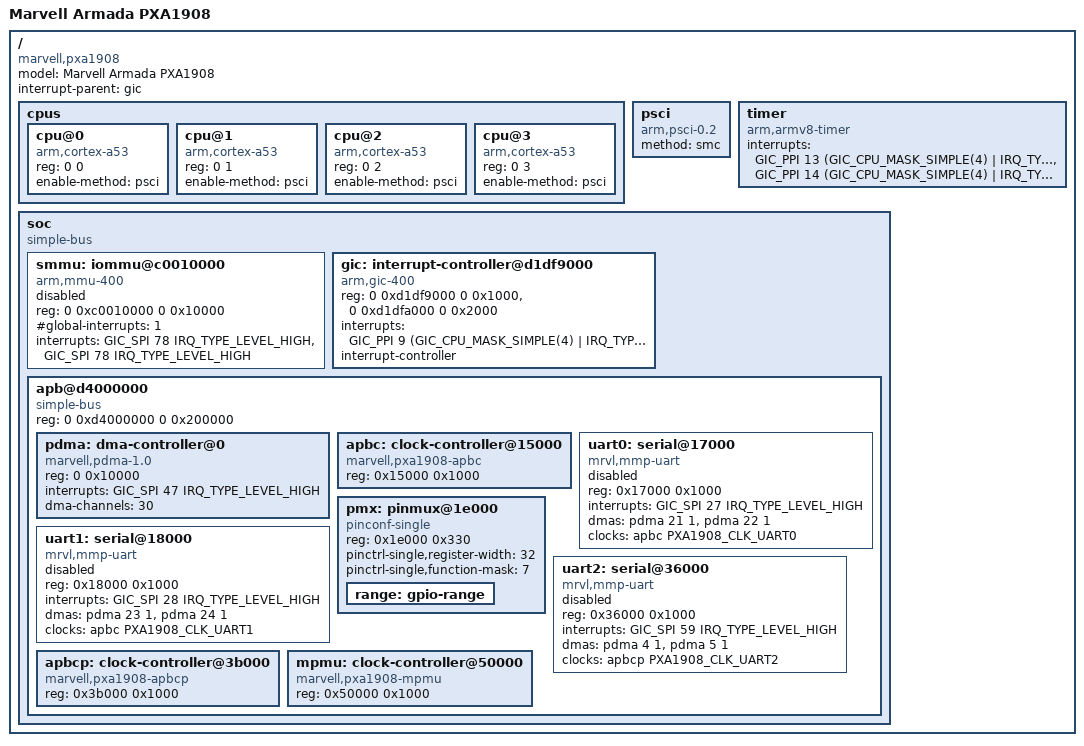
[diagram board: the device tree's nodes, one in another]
/dts-v1/;

#include <dt-bindings/interrupt-controller/arm-gic.h>
#include <dt-bindings/clock/marvell,pxa1908.h>

/ {
	model = "Marvell Armada PXA1908";
	compatible = "marvell,pxa1908";
	#address-cells = <2>;
	#size-cells = <2>;
	interrupt-parent = <&gic>;

	cpus {
		#address-cells = <2>;
		#size-cells = <0>;

		cpu@0 {
			device_type = "cpu";
			compatible = "arm,cortex-a53", "arm,armv8";
			reg = <0 0>;
			enable-method = "psci";
		};

		cpu@1 {
			device_type = "cpu";
			compatible = "arm,cortex-a53", "arm,armv8";
			reg = <0 1>;
			enable-method = "psci";
		};

		cpu@2 {
			device_type = "cpu";
			compatible = "arm,cortex-a53", "arm,armv8";
			reg = <0 2>;
			enable-method = "psci";
		};

		cpu@3 {
			device_type = "cpu";
			compatible = "arm,cortex-a53", "arm,armv8";
			reg = <0 3>;
			enable-method = "psci";
		};
	};

	psci {
		compatible = "arm,psci-0.2";
		method = "smc";
	};

	timer {
		compatible = "arm,armv8-timer";
		interrupts = <GIC_PPI 13 (GIC_CPU_MASK_SIMPLE(4) | IRQ_TYPE_LEVEL_LOW)>,
		             <GIC_PPI 14 (GIC_CPU_MASK_SIMPLE(4) | IRQ_TYPE_LEVEL_LOW)>;
	};

	soc {
		compatible = "simple-bus";
		#address-cells = <2>;
		#size-cells = <2>;
		ranges;

		smmu: iommu@c0010000 {
			compatible = "arm,mmu-400";
			reg = <0 0xc0010000 0 0x10000>;
			#global-interrupts = <1>;
			#iommu-cells = <1>;
			interrupts = <GIC_SPI 78 IRQ_TYPE_LEVEL_HIGH>,
				     <GIC_SPI 78 IRQ_TYPE_LEVEL_HIGH>;
			status = "disabled";
		};

		gic: interrupt-controller@d1df9000 {
			compatible = "arm,gic-400";
			reg = <0 0xd1df9000 0 0x1000>,
			      <0 0xd1dfa000 0 0x2000>;
			interrupts = <GIC_PPI 9 (GIC_CPU_MASK_SIMPLE(4) | IRQ_TYPE_LEVEL_LOW)>;
			interrupt-controller;
			#interrupt-cells = <3>;
		};

		apb@d4000000 {
			compatible = "simple-bus";
			reg = <0 0xd4000000 0 0x200000>;
			#address-cells = <1>;
			#size-cells = <1>;
			ranges = <0 0 0xd4000000 0x200000>;

			pdma: dma-controller@0 {
				compatible = "marvell,pdma-1.0";
				reg = <0 0x10000>;
				interrupts = <GIC_SPI 47 IRQ_TYPE_LEVEL_HIGH>;
				dma-channels = <30>;
				#dma-cells = <2>;
			};

			apbc: clock-controller@15000 {
				compatible = "marvell,pxa1908-apbc";
				reg = <0x15000 0x1000>;
				#clock-cells = <1>;
			};

			uart0: serial@17000 {
				compatible = "mrvl,mmp-uart";
				reg = <0x17000 0x1000>;
				interrupts = <GIC_SPI 27 IRQ_TYPE_LEVEL_HIGH>;
				dmas = <&pdma 21 1>,
				       <&pdma 22 1>;
				dma-names = "rx", "tx";
				clocks = <&apbc PXA1908_CLK_UART0>;
				status = "disabled";
			};

			uart1: serial@18000 {
				compatible = "mrvl,mmp-uart";
				reg = <0x18000 0x1000>;
				interrupts = <GIC_SPI 28 IRQ_TYPE_LEVEL_HIGH>;
				dmas = <&pdma 23 1>,
				       <&pdma 24 1>;
				dma-names = "rx", "tx";
				clocks = <&apbc PXA1908_CLK_UART1>;
				status = "disabled";
			};

			pmx: pinmux@1e000 {
				compatible = "pinconf-single";
				reg = <0x1e000 0x330>;
				#address-cells = <1>;
				#size-cells = <1>;
				#gpio-range-cells = <3>;
				ranges;

				#pinctrl-cells = <1>;
				pinctrl-single,register-width = <32>;
				pinctrl-single,function-mask = <7>;

				range: gpio-range {
					#pinctrl-single,gpio-range-cells = <3>;
				};
			};

			uart2: serial@36000 {
				compatible = "mrvl,mmp-uart";
				reg = <0x36000 0x1000>;
				interrupts = <GIC_SPI 59 IRQ_TYPE_LEVEL_HIGH>;
				dmas = <&pdma 4 1>,
				       <&pdma 5 1>;
				dma-names = "rx", "tx";
				clocks = <&apbcp PXA1908_CLK_UART2>;
				status = "disabled";
			};

			apbcp: clock-controller@3b000 {
				compatible = "marvell,pxa1908-apbcp";
				reg = <0x3b000 0x1000>;
				#clock-cells = <1>;
			};

			mpmu: clock-controller@50000 {
				compatible = "marvell,pxa1908-mpmu";
				reg = <0x50000 0x1000>;
				#clock-cells = <1>;
			};
		};
	};
};
